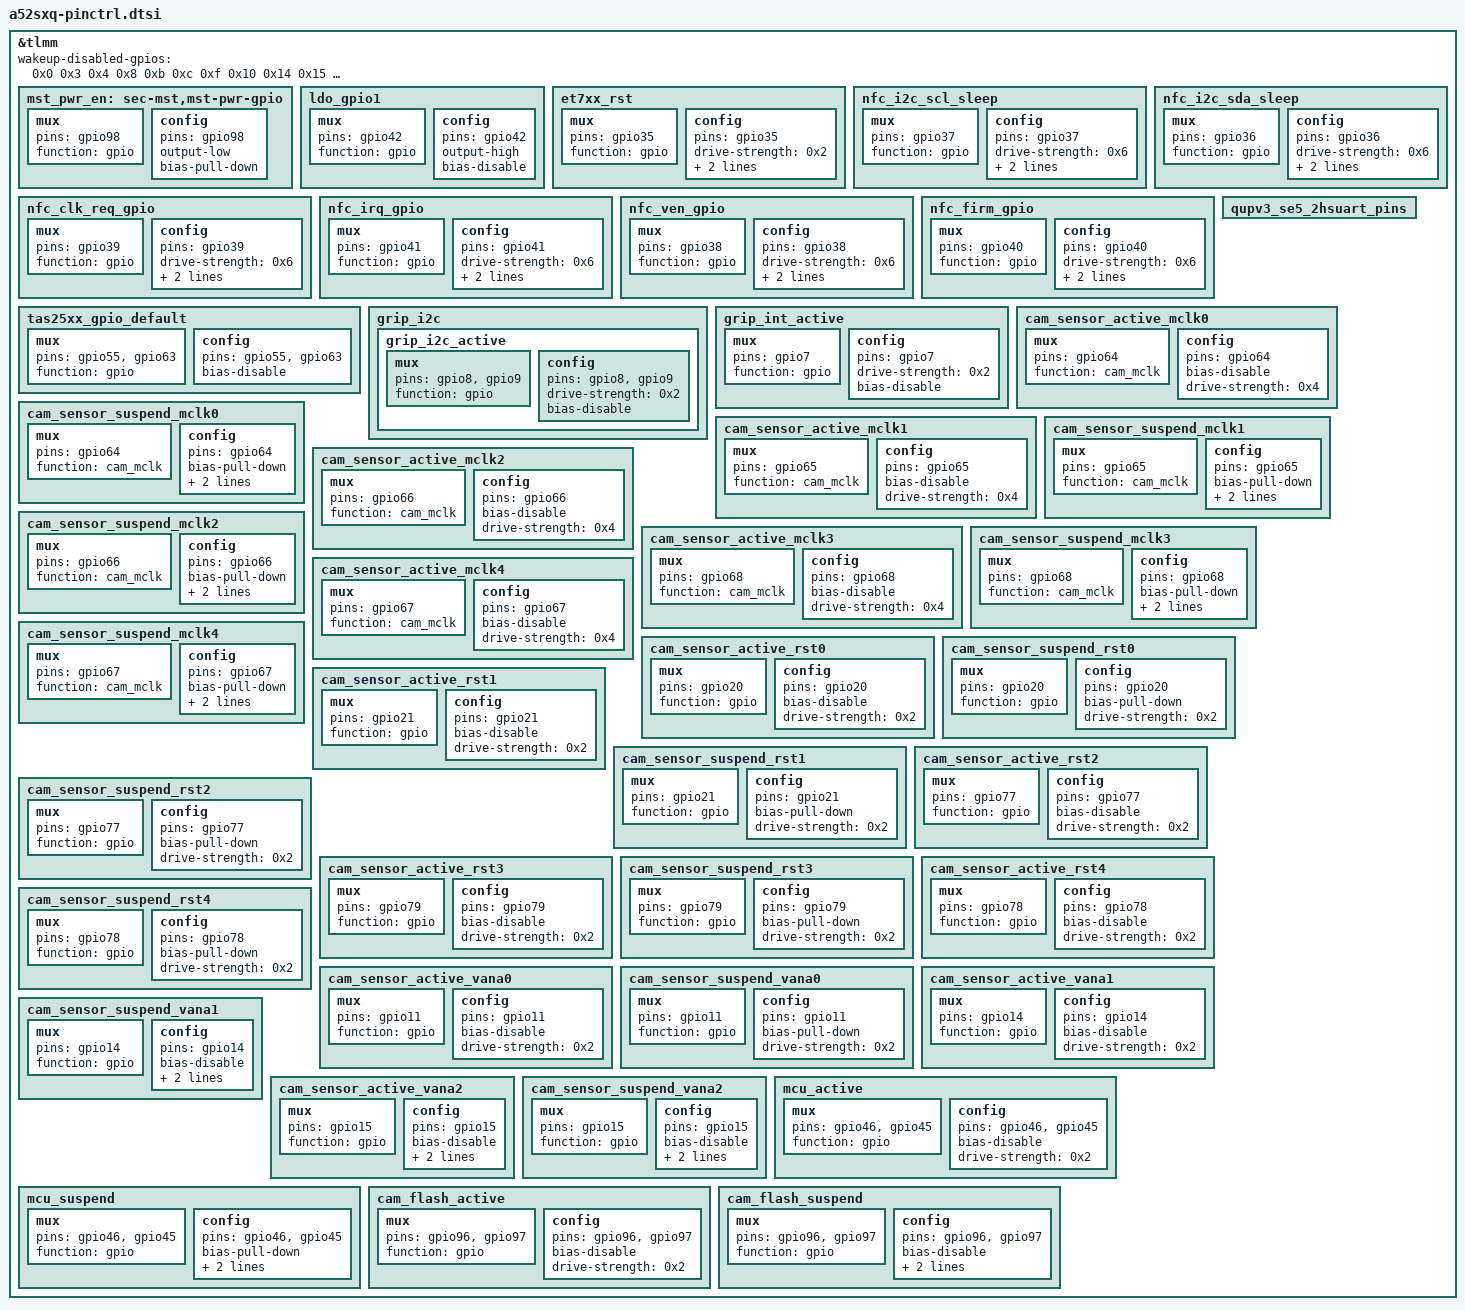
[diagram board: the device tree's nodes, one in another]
// SPDX-License-Identifier: GPL-2.0
/*
 * a52sxq board description for the Qualcomm 6.12 yupik base: pinctrl
 * GENERATED by tools/gen.py from the phone's stock dtbo (5.4 bindings, values verbatim).
 * Do not edit: hand-written 6.12 changes live in a52sxq-bsp612-fixups.dtsi.
 */

&tlmm {
	wakeup-disabled-gpios = <0x0 0x3 0x4 0x8 0xb 0xc 0xf 0x10 0x14 0x15 0x17 0x18 0x19 0x1c 0x20 0x22 0x23 0x24 0x28 0x29 0x2b 0x2c 0x2d 0x2f 0x30 0x33 0x34 0x37 0x38 0x3b 0x3c 0x3d 0x3f 0x44 0x48 0x4b 0x4d 0x4e 0x4f 0x50 0x52 0x53 0x5a 0x5d 0x5f 0x68 0x70 0x74 0x79 0x7b 0x7f 0x81 0x82 0x83 0x88 0x8d 0x8e 0x96 0x97 0x99 0x9b 0x9c 0x9d 0x9f 0xa1 0xa3 0xa6 0xac 0xae>;

	mst_pwr_en: sec-mst,mst-pwr-gpio {

		mux {
			pins = "gpio98";
			function = "gpio";
		};

		config {
			pins = "gpio98";
			output-low;
			bias-pull-down;
		};
	};

	ldo_gpio1: ldo_gpio1 {

		mux {
			pins = "gpio42";
			function = "gpio";
		};

		config {
			pins = "gpio42";
			output-high;
			bias-disable;
		};
	};

	et7xx_rst: et7xx_rst {

		mux {
			pins = "gpio35";
			function = "gpio";
		};

		config {
			pins = "gpio35";
			drive-strength = <0x2>;
			output-low;
			bias-pull-down;
		};
	};

	nfc_i2c_scl_sleep: nfc_i2c_scl_sleep {

		mux {
			pins = "gpio37";
			function = "gpio";
		};

		config {
			pins = "gpio37";
			drive-strength = <0x6>;
			input-enable;
			bias-disable;
		};
	};

	nfc_i2c_sda_sleep: nfc_i2c_sda_sleep {

		mux {
			pins = "gpio36";
			function = "gpio";
		};

		config {
			pins = "gpio36";
			drive-strength = <0x6>;
			input-enable;
			bias-disable;
		};
	};

	nfc_clk_req_gpio: nfc_clk_req_gpio {

		mux {
			pins = "gpio39";
			function = "gpio";
		};

		config {
			pins = "gpio39";
			drive-strength = <0x6>;
			input-enable;
			bias-pull-down;
		};
	};

	nfc_irq_gpio: nfc_irq_gpio {

		mux {
			pins = "gpio41";
			function = "gpio";
		};

		config {
			pins = "gpio41";
			drive-strength = <0x6>;
			input-enable;
			bias-pull-down;
		};
	};

	nfc_ven_gpio: nfc_ven_gpio {

		mux {
			pins = "gpio38";
			function = "gpio";
		};

		config {
			pins = "gpio38";
			drive-strength = <0x6>;
			output-high;
			bias-disable;
		};
	};

	nfc_firm_gpio: nfc_firm_gpio {

		mux {
			pins = "gpio40";
			function = "gpio";
		};

		config {
			pins = "gpio40";
			drive-strength = <0x6>;
			output-low;
			bias-disable;
		};
	};

	qupv3_se5_2hsuart_pins {
	};

	tas25xx_gpio_default: tas25xx_gpio_default {

		mux {
			pins = "gpio55", "gpio63";
			function = "gpio";
		};

		config {
			pins = "gpio55", "gpio63";
			bias-disable;
		};
	};

	grip_i2c {

		grip_i2c_active: grip_i2c_active {

			mux {
				pins = "gpio8", "gpio9";
				function = "gpio";
			};

			config {
				pins = "gpio8", "gpio9";
				drive-strength = <0x2>;
				bias-disable;
			};
		};
	};

	grip_int_active: grip_int_active {

		mux {
			pins = "gpio7";
			function = "gpio";
		};

		config {
			pins = "gpio7";
			drive-strength = <0x2>;
			bias-disable;
		};
	};

	cam_sensor_active_mclk0: cam_sensor_active_mclk0 {

		mux {
			pins = "gpio64";
			function = "cam_mclk";
		};

		config {
			pins = "gpio64";
			bias-disable;
			drive-strength = <0x4>;
		};
	};

	cam_sensor_suspend_mclk0: cam_sensor_suspend_mclk0 {

		mux {
			pins = "gpio64";
			function = "cam_mclk";
		};

		config {
			pins = "gpio64";
			bias-pull-down;
			drive-strength = <0x4>;
			output-low;
		};
	};

	cam_sensor_active_mclk1: cam_sensor_active_mclk1 {

		mux {
			pins = "gpio65";
			function = "cam_mclk";
		};

		config {
			pins = "gpio65";
			bias-disable;
			drive-strength = <0x4>;
		};
	};

	cam_sensor_suspend_mclk1: cam_sensor_suspend_mclk1 {

		mux {
			pins = "gpio65";
			function = "cam_mclk";
		};

		config {
			pins = "gpio65";
			bias-pull-down;
			drive-strength = <0x4>;
			output-low;
		};
	};

	cam_sensor_active_mclk2: cam_sensor_active_mclk2 {

		mux {
			pins = "gpio66";
			function = "cam_mclk";
		};

		config {
			pins = "gpio66";
			bias-disable;
			drive-strength = <0x4>;
		};
	};

	cam_sensor_suspend_mclk2: cam_sensor_suspend_mclk2 {

		mux {
			pins = "gpio66";
			function = "cam_mclk";
		};

		config {
			pins = "gpio66";
			bias-pull-down;
			drive-strength = <0x4>;
			output-low;
		};
	};

	cam_sensor_active_mclk3: cam_sensor_active_mclk3 {

		mux {
			pins = "gpio68";
			function = "cam_mclk";
		};

		config {
			pins = "gpio68";
			bias-disable;
			drive-strength = <0x4>;
		};
	};

	cam_sensor_suspend_mclk3: cam_sensor_suspend_mclk3 {

		mux {
			pins = "gpio68";
			function = "cam_mclk";
		};

		config {
			pins = "gpio68";
			bias-pull-down;
			drive-strength = <0x4>;
			output-low;
		};
	};

	cam_sensor_active_mclk4: cam_sensor_active_mclk4 {

		mux {
			pins = "gpio67";
			function = "cam_mclk";
		};

		config {
			pins = "gpio67";
			bias-disable;
			drive-strength = <0x4>;
		};
	};

	cam_sensor_suspend_mclk4: cam_sensor_suspend_mclk4 {

		mux {
			pins = "gpio67";
			function = "cam_mclk";
		};

		config {
			pins = "gpio67";
			bias-pull-down;
			drive-strength = <0x4>;
			output-low;
		};
	};

	cam_sensor_active_rst0: cam_sensor_active_rst0 {

		mux {
			pins = "gpio20";
			function = "gpio";
		};

		config {
			pins = "gpio20";
			bias-disable;
			drive-strength = <0x2>;
		};
	};

	cam_sensor_suspend_rst0: cam_sensor_suspend_rst0 {

		mux {
			pins = "gpio20";
			function = "gpio";
		};

		config {
			pins = "gpio20";
			bias-pull-down;
			drive-strength = <0x2>;
		};
	};

	cam_sensor_active_rst1: cam_sensor_active_rst1 {

		mux {
			pins = "gpio21";
			function = "gpio";
		};

		config {
			pins = "gpio21";
			bias-disable;
			drive-strength = <0x2>;
		};
	};

	cam_sensor_suspend_rst1: cam_sensor_suspend_rst1 {

		mux {
			pins = "gpio21";
			function = "gpio";
		};

		config {
			pins = "gpio21";
			bias-pull-down;
			drive-strength = <0x2>;
		};
	};

	cam_sensor_active_rst2: cam_sensor_active_rst2 {

		mux {
			pins = "gpio77";
			function = "gpio";
		};

		config {
			pins = "gpio77";
			bias-disable;
			drive-strength = <0x2>;
		};
	};

	cam_sensor_suspend_rst2: cam_sensor_suspend_rst2 {

		mux {
			pins = "gpio77";
			function = "gpio";
		};

		config {
			pins = "gpio77";
			bias-pull-down;
			drive-strength = <0x2>;
		};
	};

	cam_sensor_active_rst3: cam_sensor_active_rst3 {

		mux {
			pins = "gpio79";
			function = "gpio";
		};

		config {
			pins = "gpio79";
			bias-disable;
			drive-strength = <0x2>;
		};
	};

	cam_sensor_suspend_rst3: cam_sensor_suspend_rst3 {

		mux {
			pins = "gpio79";
			function = "gpio";
		};

		config {
			pins = "gpio79";
			bias-pull-down;
			drive-strength = <0x2>;
		};
	};

	cam_sensor_active_rst4: cam_sensor_active_rst4 {

		mux {
			pins = "gpio78";
			function = "gpio";
		};

		config {
			pins = "gpio78";
			bias-disable;
			drive-strength = <0x2>;
		};
	};

	cam_sensor_suspend_rst4: cam_sensor_suspend_rst4 {

		mux {
			pins = "gpio78";
			function = "gpio";
		};

		config {
			pins = "gpio78";
			bias-pull-down;
			drive-strength = <0x2>;
		};
	};

	cam_sensor_active_vana0: cam_sensor_active_vana0 {

		mux {
			pins = "gpio11";
			function = "gpio";
		};

		config {
			pins = "gpio11";
			bias-disable;
			drive-strength = <0x2>;
		};
	};

	cam_sensor_suspend_vana0: cam_sensor_suspend_vana0 {

		mux {
			pins = "gpio11";
			function = "gpio";
		};

		config {
			pins = "gpio11";
			bias-pull-down;
			drive-strength = <0x2>;
		};
	};

	cam_sensor_active_vana1: cam_sensor_active_vana1 {

		mux {
			pins = "gpio14";
			function = "gpio";
		};

		config {
			pins = "gpio14";
			bias-disable;
			drive-strength = <0x2>;
		};
	};

	cam_sensor_suspend_vana1: cam_sensor_suspend_vana1 {

		mux {
			pins = "gpio14";
			function = "gpio";
		};

		config {
			pins = "gpio14";
			bias-disable;
			drive-strength = <0x2>;
			output-low;
		};
	};

	cam_sensor_active_vana2: cam_sensor_active_vana2 {

		mux {
			pins = "gpio15";
			function = "gpio";
		};

		config {
			pins = "gpio15";
			bias-disable;
			drive-strength = <0x2>;
			output-high;
		};
	};

	cam_sensor_suspend_vana2: cam_sensor_suspend_vana2 {

		mux {
			pins = "gpio15";
			function = "gpio";
		};

		config {
			pins = "gpio15";
			bias-disable;
			drive-strength = <0x2>;
			output-low;
		};
	};

	mcu_active: mcu_active {

		mux {
			pins = "gpio46", "gpio45";
			function = "gpio";
		};

		config {
			pins = "gpio46", "gpio45";
			bias-disable;
			drive-strength = <0x2>;
		};
	};

	mcu_suspend: mcu_suspend {

		mux {
			pins = "gpio46", "gpio45";
			function = "gpio";
		};

		config {
			pins = "gpio46", "gpio45";
			bias-pull-down;
			drive-strength = <0x2>;
			output-low;
		};
	};

	cam_flash_active: cam_flash_active {

		mux {
			pins = "gpio96", "gpio97";
			function = "gpio";
		};

		config {
			pins = "gpio96", "gpio97";
			bias-disable;
			drive-strength = <0x2>;
		};
	};

	cam_flash_suspend: cam_flash_suspend {

		mux {
			pins = "gpio96", "gpio97";
			function = "gpio";
		};

		config {
			pins = "gpio96", "gpio97";
			bias-disable;
			drive-strength = <0x2>;
			output-low;
		};
	};
};

